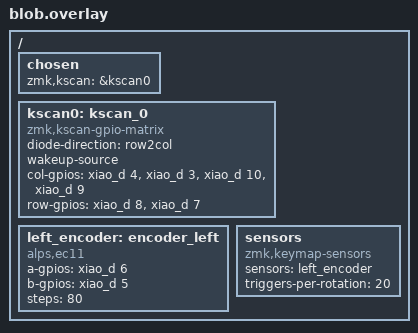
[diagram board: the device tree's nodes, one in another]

/ {
    chosen {
        zmk,kscan = &kscan0;
    };

    kscan0: kscan_0 {
        compatible = "zmk,kscan-gpio-matrix";
        diode-direction = "row2col";
        wakeup-source;

        col-gpios
            = <&xiao_d 4  (GPIO_ACTIVE_HIGH | GPIO_PULL_DOWN)>
            , <&xiao_d 3  (GPIO_ACTIVE_HIGH | GPIO_PULL_DOWN)>
            , <&xiao_d 10 (GPIO_ACTIVE_HIGH | GPIO_PULL_DOWN)>
            , <&xiao_d 9  (GPIO_ACTIVE_HIGH | GPIO_PULL_DOWN)>
            ;

        row-gpios
            = <&xiao_d 8 (GPIO_ACTIVE_HIGH)>
            , <&xiao_d 7 (GPIO_ACTIVE_HIGH)>
            ;
    };


    left_encoder: encoder_left {
        compatible = "alps,ec11";
        a-gpios = <&xiao_d 6 (GPIO_ACTIVE_HIGH | GPIO_PULL_UP)>;
        b-gpios = <&xiao_d 5 (GPIO_ACTIVE_HIGH | GPIO_PULL_UP)>;
        steps = <80>;
        status = "okay";
    };

    sensors: sensors {
        compatible = "zmk,keymap-sensors";
        sensors = <&left_encoder>;
        triggers-per-rotation = <20>;
    };

};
